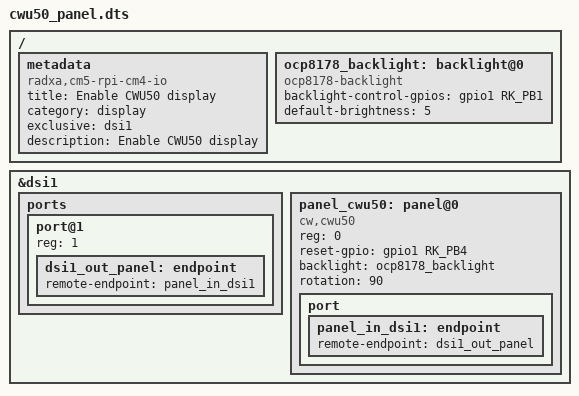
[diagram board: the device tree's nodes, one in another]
/dts-v1/;
/plugin/;
#include <dt-bindings/interrupt-controller/irq.h>
#include <dt-bindings/gpio/gpio.h>
#include <dt-bindings/pinctrl/rockchip.h>
/ {

	metadata {
		title = "Enable CWU50 display";
		compatible = "radxa,cm5-rpi-cm4-io";
		category = "display";
		exclusive = "dsi1";
		description = "Enable CWU50 display";
	};
	
	fragment@0 {
		target=<&dsi1>;
		__overlay__ {
			#address-cells = <1>;
			#size-cells = <0>;
			status = "okay";
			
		ports {
			#address-cells = <1>;
			#size-cells = <0>;

			port@1 {
				reg = <1>;
				dsi1_out_panel: endpoint {
					remote-endpoint = <&panel_in_dsi1>;
				};
			};
		};
			
			panel_cwu50: panel@0 {
				compatible = "cw,cwu50";
				reg = <0>;
				reset-gpio = <&gpio1 RK_PB4 GPIO_ACTIVE_HIGH>;
				backlight = <&ocp8178_backlight>;
				rotation = <90>;
				port {
					panel_in_dsi1: endpoint {
						remote-endpoint = <&dsi1_out_panel>;
					};
				};
			};
			
		};
	};
	fragment@1 {
		target-path = "/";
		__overlay__  {
			ocp8178_backlight: backlight@0 {
				compatible = "ocp8178-backlight";
				backlight-control-gpios = <&gpio1 RK_PB1 GPIO_ACTIVE_HIGH>;
				default-brightness = <5>;
			};
		};
	};
};
